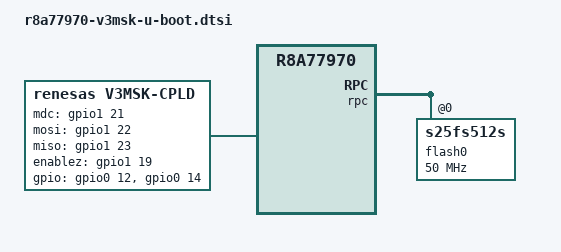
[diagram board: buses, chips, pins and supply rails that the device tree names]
// SPDX-License-Identifier: GPL-2.0
/*
 * Device Tree Source extras for U-Boot for the V3MSK board
 *
 * Copyright (C) 2019 Cogent Embedded, Inc.
 */

#include <dt-bindings/gpio/gpio.h>

/ {
	aliases {
		spi0 = &rpc;
	};

	cpld {
		compatible = "renesas,v3msk-cpld";
		status = "okay";
		gpio-mdc = <&gpio1 21 0>;
		gpio-mosi = <&gpio1 22 0>;
		gpio-miso = <&gpio1 23 0>;
		gpio-enablez = <&gpio1 19 0>;
		/* Disable V3MSK Videobox Mini CANFD PHY */
		gpios = <&gpio0 12 0>, <&gpio0 14 0>;
	};
};

&rpc {
	status = "okay";
	#address-cells = <1>;
	#size-cells = <0>;

	flash0: spi-flash@0 {
		#address-cells = <1>;
		#size-cells = <1>;
		compatible = "s25fs512s", "spi-flash", "jedec,spi-nor";
		spi-max-frequency = <50000000>;
		spi-tx-bus-width = <1>;
		spi-rx-bus-width = <1>;
		reg = <0>;
		status = "okay";
	};
};
